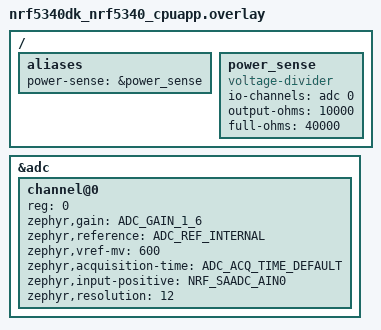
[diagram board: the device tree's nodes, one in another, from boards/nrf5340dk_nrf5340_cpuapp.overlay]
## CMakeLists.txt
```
cmake_minimum_required(VERSION 3.13.1)

find_package(
  Zephyr
  REQUIRED
  HINTS
  $ENV{ZEPHYR_BASE}
)
project(
  ble_audio
)

include(tools/cmake/version.cmake)

target_sources(
  app
  PRIVATE src/main.c
)

zephyr_include_directories(src)

add_subdirectory(src/common)
add_subdirectory(src/core)
add_subdirectory(src/middlewares)
add_subdirectory(src/application)
```

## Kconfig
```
menu "BLE Audio"

# TODO: add BLE Audio specific Kconfig options here as functionality is implemented

endmenu

menu "Zephyr Kernel"
source "Kconfig.zephyr"
endmenu
```

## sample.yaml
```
sample:
  name: BLE Audio headset boot (HIL)
  description: >
    Flashes the real image onto a physical nRF5340 DK and checks its
    actual boot log (Bluetooth init, advertising start) over UART. Not
    run by `make test` - needs real hardware and a filled-in
    tools/hardware-map.yml (see tools/hardware-map.example.yml). Run via
    `make test-hil`.
tests:
  ble_audio.hil_boot:
    # Console harness: Twister itself watches the UART for these two
    # lines, in order - no pytest/twister_harness needed. That plugin
    # only earns its keep for HIL scenarios that need actual Python
    # logic (driving a second device, multi-step interaction); a fixed
    # boot-log check doesn't, and pytest was real, avoidable fragility
    # here (see docs/hil_testing.md's Bug 1).
    harness: console
    harness_config:
      type: multi_line
      regex:
        - "Bluetooth initialized"
        - "Advertising started"
    platform_allow: nrf5340dk/nrf5340/cpuapp
    extra_configs:
      # Production prj.conf logs over RTT only (CONFIG_UART_CONSOLE=n).
      # Twister's hardware harness reads a UART device, so route console
      # output there instead, for this HIL run only - the shipped image
      # is unaffected.
      - CONFIG_LOG_BACKEND_UART=y
      - CONFIG_LOG_BACKEND_RTT=n
      - CONFIG_UART_CONSOLE=y
    tags:
      - hil
```

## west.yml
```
manifest:
  remotes:
    - name: ncs
      url-base: https://github.com/nrfconnect
  projects:
    - name: sdk_nrf
      repo-path: sdk-nrf
      path: nrf
      remote: ncs
      revision: v2.7.0
      import: true
  self:
    path: ble_audio
```

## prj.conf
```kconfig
# Baseline configuration for the LE Audio unicast server (headset) role.
# BT Audio/ISO/ASCS options are modeled on
# zephyr/samples/bluetooth/unicast_audio_server's prj.conf - this gets the
# device advertising and accepting an ASE.

CONFIG_ASSERT=y
CONFIG_ASSERT_LEVEL=2
CONFIG_THREAD_NAME=y
CONFIG_THREAD_STACK_INFO=y
CONFIG_THREAD_MONITOR=y
CONFIG_INIT_STACKS=y
CONFIG_REBOOT=y

# Bluetooth
CONFIG_BT=y
CONFIG_BT_DEVICE_NAME="BLE-Audio"
CONFIG_BT_PERIPHERAL=y
CONFIG_BT_EXT_ADV=y

# LE Audio unicast server (headset). Sink only for now (receive + play
# back) - no source ASE, since mic capture isn't implemented yet.
CONFIG_BT_ISO_PERIPHERAL=y
CONFIG_BT_AUDIO=y
CONFIG_BT_BAP_UNICAST_SERVER=y
CONFIG_BT_ASCS=y
CONFIG_BT_ASCS_ASE_SNK_COUNT=1
CONFIG_BT_ASCS_ASE_SRC_COUNT=0
# Support an ISO channel per ASE
CONFIG_BT_ISO_MAX_CHAN=1
# Mandatory to support at least 1 for ASCS
CONFIG_BT_ATT_PREPARE_COUNT=1

# LC3 codec (decode only - no encoder needed for a sink-only headset).
# CONFIG_LIBLC3 depends on FPU; FPU_SHARING preserves FP registers across
# context switches so the codec can share the CPU with the BT stack.
CONFIG_FPU=y
CONFIG_FPU_SHARING=y
CONFIG_LIBLC3=y

# I2S audio output, GPIO for LED/button, ADC for input power sensing
CONFIG_I2S=y
CONFIG_GPIO=y
CONFIG_ADC=y

# Logging
CONFIG_LOG=y
CONFIG_LOG_MODE_DEFERRED=y
CONFIG_LOG_BACKEND_RTT=y
CONFIG_LOG_BACKEND_UART=n
CONFIG_LOG_PRINTK=y
CONFIG_LOG_DEFAULT_LEVEL=3
CONFIG_USE_SEGGER_RTT=y
CONFIG_RTT_CONSOLE=y
CONFIG_UART_CONSOLE=n
```

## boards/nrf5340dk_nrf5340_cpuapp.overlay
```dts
/*
 * Input power sense: a resistor divider (30k top / 10k bottom, wired
 * into A0/P0.04/AIN0 - see arduino_adc's io-channel-map in
 * nrf5340_cpuapp_common.dtsi) scales board input voltage down into the
 * SAADC's measurable range. &adc is already "okay" at the board level;
 * only the channel and the voltage-divider node are added here.
 *
 * Reference/gain follow zephyr/samples/drivers/adc/adc_dt's nrf52840dk
 * overlay (ADC_REF_INTERNAL @ 600 mV, 1/6 gain -> 3.6V full-scale at the
 * pin), rather than ADC_REF_VDD (used by nrf5340_audio_dk's own
 * board_id voltage-divider) - internal reference doesn't depend on VDD
 * regulation accuracy, so the mV math power_handler does is exact.
 *
 * output-ohms/full-ohms = 10k/40k (ratio 4) maps the 3.6V pin ceiling to
 * a 14.4V real-world ceiling, comfortable headroom above the 4.0V
 * high/low power threshold app_streamctrl.c checks against.
 */

#include <zephyr/dt-bindings/adc/adc.h>
#include <zephyr/dt-bindings/adc/nrf-adc.h>

/ {
	aliases {
		power-sense = &power_sense;
	};

	power_sense: power_sense {
		compatible = "voltage-divider";
		io-channels = <&adc 0>;
		output-ohms = <10000>;
		full-ohms = <40000>;
	};
};

&adc {
	#address-cells = <1>;
	#size-cells = <0>;

	channel@0 {
		reg = <0>;
		zephyr,gain = "ADC_GAIN_1_6";
		zephyr,reference = "ADC_REF_INTERNAL";
		zephyr,vref-mv = <600>;
		zephyr,acquisition-time = <ADC_ACQ_TIME_DEFAULT>;
		zephyr,input-positive = <NRF_SAADC_AIN0>;
		zephyr,resolution = <12>;
	};
};
```

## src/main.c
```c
#include <zephyr/kernel.h>

#include "app_streamctrl.h"

int main(void)
{
	return app_streamctrl_start();
}
```
